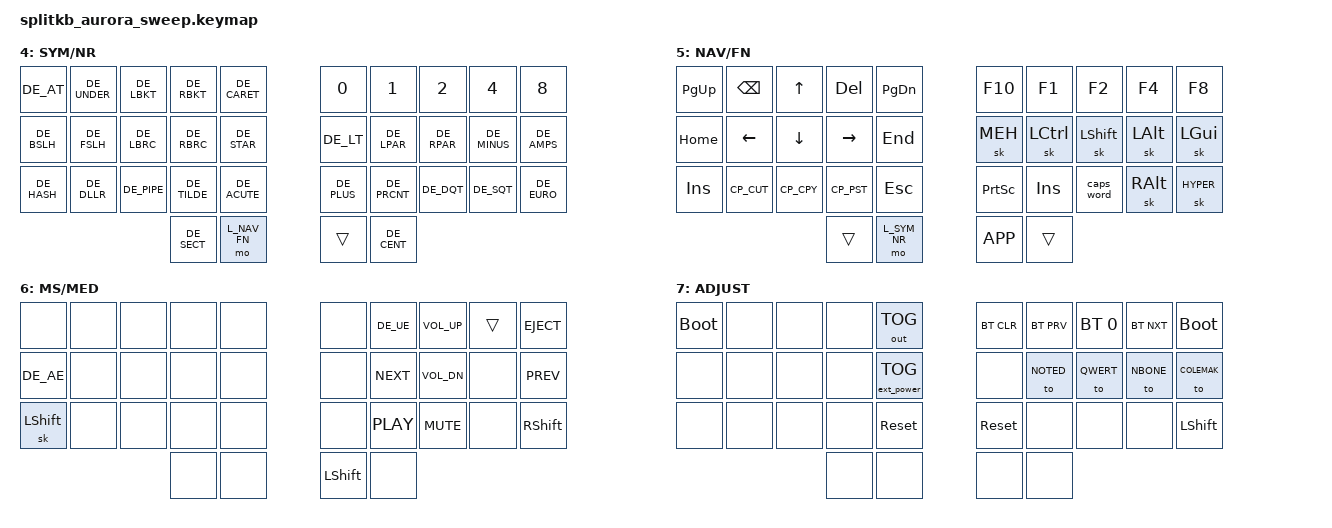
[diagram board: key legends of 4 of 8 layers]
/*
 * Copyright (c) 2022 The ZMK Contributors
 *
 * SPDX-License-Identifier: MIT
 */

#include <behaviors.dtsi>
#include <dt-bindings/zmk/keys.h>
#include <dt-bindings/zmk/bt.h>
#include <dt-bindings/zmk/outputs.h>
/* #include <dt-bindings/zmk/rgb.h> */
#include <dt-bindings/zmk/ext_power.h>
#include "custom_keys.h"
#include "custom_combos.h"

&mt {
  flavor = "tap-preferred";
};
&caps_word {
  continue-list = <DE_UNDER DE_MINUS BACKSPACE DELETE>;
};

// pin 1 is blocked by rgb, so use pin 16 as I have no encoders installed
/* nice_view_spi: &spi0 {
                  compatible = "nordic,nrf-spim";
                  pinctrl-0 = <&spi0_default>;
                  pinctrl-1 = <&spi0_sleep>;
                  pinctrl-names = "default", "sleep";
                  cs-gpios = <&pro_micro 16 GPIO_ACTIVE_HIGH>;  // default is D1 in the pinout
              }; */

/ {
  conditional_layers {
    compatible = "zmk,conditional-layers";
    tri_layer {
      if-layers = <L_SYM_NR L_NAV_FN>;
      then-layer = <L_ADJUST>;
    };
  };

  keymap {
    compatible = "zmk,keymap";

    // 0. NOTED
    noted_layer {
      display-name = "NOTED";
      bindings = <
        // ┌─────┬─────┬─────┬─────┬─────┐     ┌─────┬─────┬─────┬─────┬─────┐
        // │  x  │  v  │  l  │  c  │  w  │     │  k  │  h  │  g  │ 4/f │  q  │
        // ├─────┼─────┼─────┼─────┼─────┤     ├─────┼─────┼─────┼─────┼─────┤
        // │  u  │  i  │  a  │  e  │  o  │     │  s  │  n  │  r  │  t  │  d  │
        // ├─────┼─────┼─────┼─────┼─────┤     ├─────┼─────┼─────┼─────┼─────┤
        // │  y  │  ö  │  ß  │  p  │  z  │     │  b  │  m  │  ,  │  .  │  j  │
        // └─────┴─────┴─────┼─────┼─────┤     ├─────┼─────┼─────┴─────┴─────┘
        //                   │2/Tab│1/Ret│     │1/Spc│2/Esc│
        //                   └─────┴─────┘     └─────┴─────┘
        &kp DE_X      &kp DE_V      &kp DE_L      &kp DE_C      &kp DE_W          &kp DE_K       &kp DE_H      &kp DE_G        MSMD(DE_F)    &kp DE_Q
        &kp DE_U      &kp DE_I     HRML(DE_A,         DE_E,         DE_O)         HRMR(DE_S,         DE_N,         DE_R)       &kp DE_T      &kp DE_D
        LSH(DE_Y)     &kp DE_OE     &kp DE_SZ     &kp DE_Q      &kp DE_OE         &kp DE_Y       &kp DE_Z      &kp DE_COMMA    &kp DE_DOT    RSH(DE_K)
        /**/                                      NAVFN_TAB     SYMNR_RET         SYMNR_SPC      NAVFN_ESC
        >;
    };

    // 1. QWERTZ
    default_layer {
      display-name = "QWERTZ";
      bindings = <
        // ┌─────┬─────┬─────┬─────┬─────┐     ┌─────┬─────┬─────┬─────┬─────┐
        // │  q  │  w  │  e  │  r  │  t  │     │  z  │  u  │  i  │ 4/o │  p  │
        // ├─────┼─────┼─────┼─────┼─────┤     ├─────┼─────┼─────┼─────┼─────┤
        // │  a  │  s  │  d  │  f  │  g  │     │  h  │  j  │  k  │  l  │  ö  │
        // ├─────┼─────┼─────┼─────┼─────┤     ├─────┼─────┼─────┼─────┼─────┤
        // │  y  │  x  │  c  │  v  │  b  │     │  n  │  m  │  ,  │  .  │  ß  │
        // └─────┴─────┴─────┼─────┼─────┤     ├─────┼─────┼─────┴─────┴─────┘
        //                   │2/Tab│1/Ret│     │1/Spc│2/Esc│
        //                   └─────┴─────┘     └─────┴─────┘
        &kp DE_Q      &kp DE_W      &kp DE_E      &kp DE_R      &kp DE_T          &kp DE_Z       &kp DE_U      &kp DE_I        MSMD(DE_O)    &kp DE_P
        &kp DE_A      &kp DE_S     HRML(DE_D,         DE_F,         DE_G)         HRMR(DE_H,         DE_J,         DE_K)       &kp DE_L      &kp DE_OE
        LSH(DE_Y)     &kp DE_X      &kp DE_C      &kp DE_V      &kp DE_B          &kp DE_N       &kp DE_M      &kp DE_COMMA    &kp DE_DOT    RSH(DE_SZ)
        /**/                                      NAVFN_TAB     SYMNR_RET         SYMNR_SPC      NAVFN_ESC
        >;
    };

    // 2. BONE
    bone_layer {
      display-name = "BONE";
      bindings = <
        // ┌─────┬─────┬─────┬─────┬─────┐     ┌─────┬─────┬─────┬─────┬─────┐
        // │  j  │  d  │  u  │  a  │  x  │     │  p  │  h  │  l  │ 4/m │  w  │
        // ├─────┼─────┼─────┼─────┼─────┤     ├─────┼─────┼─────┼─────┼─────┤
        // │  c  │  t  │  i  │  e  │  o  │     │  b  │  n  │  r  │  s  │  g  │
        // ├─────┼─────┼─────┼─────┼─────┤     ├─────┼─────┼─────┼─────┼─────┤
        // │  f  │  v  │  ß  │  q  │  ö  │     │  y  │  z  │  ,  │  .  │  k  │
        // └─────┴─────┴─────┼─────┼─────┤     ├─────┼─────┼─────┴─────┴─────┘
        //                   │2/Tab│1/Ret│     │1/Spc│2/Esc│
        //                   └─────┴─────┘     └─────┴─────┘
        &kp DE_J      &kp DE_D      &kp DE_U      &kp DE_A      &kp DE_X          &kp DE_P       &kp DE_H      &kp DE_L        MSMD(DE_M)    &kp DE_W
        &kp DE_C      &kp DE_T     HRML(DE_I,         DE_E,         DE_O)         HRMR(DE_B,         DE_N,         DE_R)       &kp DE_S      &kp DE_G
        LSH(DE_F)     &kp DE_V      &kp DE_SZ     &kp DE_Q      &kp DE_OE         &kp DE_Y       &kp DE_Z      &kp DE_COMMA    &kp DE_DOT    RSH(DE_K)
        /**/                                      NAVFN_TAB     SYMNR_RET         SYMNR_SPC      NAVFN_ESC
        >;
    };

    // 3. COLEMAK
    colemak_layer {
      display-name = "COLEMAK";
      bindings = <
        // ┌─────┬─────┬─────┬─────┬─────┐     ┌─────┬─────┬─────┬─────┬─────┐
        // │  q  │  w  │  f  │  p  │  b  │     │  j  │  l  │  u  │ 4/z │  ö  │
        // ├─────┼─────┼─────┼─────┼─────┤     ├─────┼─────┼─────┼─────┼─────┤
        // │  a  │  r  │  s  │  t  │  g  │     │  m  │  n  │  e  │  i  │  o  │
        // ├─────┼─────┼─────┼─────┼─────┤     ├─────┼─────┼─────┼─────┼─────┤
        // │  y  │  x  │  c  │  v  │  b  │     │  n  │  m  │  ,  │  .  │  ß  │
        // └─────┴─────┴─────┼─────┼─────┤     ├─────┼─────┼─────┴─────┴─────┘
        //                   │2/Tab│1/Ret│     │1/Spc│2/Esc│
        //                   └─────┴─────┘     └─────┴─────┘
        &kp DE_Q      &kp DE_W      &kp DE_F      &kp DE_P      &kp DE_B          &kp DE_J       &kp DE_L      &kp DE_U        MSMD(DE_Z)    &kp DE_OE
        &kp DE_A      &kp DE_R     HRML(DE_S,         DE_T,         DE_G)         HRMR(DE_M,         DE_N,         DE_E)       &kp DE_I      &kp DE_O
        LSH(DE_Y)     &kp DE_X      &kp DE_C      &kp DE_D      &kp DE_V          &kp DE_K       &kp DE_H      &kp DE_COMMA    &kp DE_DOT    RSH(DE_SZ)
        /**/                                      NAVFN_TAB     SYMNR_RET         SYMNR_SPC      NAVFN_ESC
        >;
    };

    // 4. L_SYM_NR
    symbol_number_layer {
      display-name = "SYM/NR";
      bindings = <
        // ┌─────┬─────┬─────┬─────┬─────┐     ┌─────┬─────┬─────┬─────┬─────┐
        // │  @  │  _  │  [  │  ]  │ ^ ° │     │ 0 = │ 1 ! │ 2 " │ 4 $ │ 8 ( │
        // ├─────┼─────┼─────┼─────┼─────┤     ├─────┼─────┼─────┼─────┼─────┤
        // │  \  │  /  │  {  │  }  │  *  │     │ < > │  (  │  )  │ - _ │  &  │
        // ├─────┼─────┼─────┼─────┼─────┤     ├─────┼─────┼─────┼─────┼─────┤
        // │ # ' │  $  │  |  │  ~  │  ´  │     │ + * │  %  │  "  │  '  │  €  │
        // └─────┴─────┴─────┼─────┼─────┤     ├─────┼─────┼─────┴─────┴─────┘
        //                   │ (§) │ ___ │     │ ___ │  ¢  │
        //                   └─────┴─────┘     └─────┴─────┘
        &kp DE_AT     &kp DE_UNDER  &kp DE_LBKT   &kp DE_RBKT   &kp DE_CARET      &kp N0        &kp N1        &kp N2        &kp N4        &kp N8
        &kp DE_BSLH   &kp DE_FSLH   &kp DE_LBRC   &kp DE_RBRC   &kp DE_STAR       &kp DE_LT     &kp DE_LPAR   &kp DE_RPAR   &kp DE_MINUS  &kp DE_AMPS
        &kp DE_HASH   &kp DE_DLLR   &kp DE_PIPE   &kp DE_TILDE  &kp DE_ACUTE      &kp DE_PLUS   &kp DE_PRCNT  &kp DE_DQT    &kp DE_SQT    &kp DE_EURO
                                                  &kp DE_SECT   &mo L_NAV_FN      &trans        &kp DE_CENT
        >;
    };

    // 5. L_NAV_FN
    navigation_function_layer {
      display-name = "NAV/FN";
      bindings = <
        // ┌─────┬─────┬─────┬─────┬─────┐     ┌─────┬─────┬─────┬─────┬─────┐
        // │PgUp │ BSp │  ↑  │ Del │PgDn │     │ F10 │  F1 │  F2 │  F4 │  F8 │
        // ├─────┼─────┼─────┼─────┼─────┤     ├─────┼─────┼─────┼─────┼─────┤
        // │Home │  ←  │  ↓  │  →  │ End │     │OsMeh│OsCtl│OsSft│OsAlt│OsGui│
        // ├─────┼─────┼─────┼─────┼─────┤     ├─────┼─────┼─────┼─────┼─────┤
        // │ Ins │ Cut │Copy │Paste│ ESC │     │PrScr│ Ins │CapsW│OsAGr│OsHyp│
        // └─────┴─────┴─────┼─────┼─────┤     ├─────┼─────┼─────┴─────┴─────┘
        //                   │     │     │     │ App │     │
        //                   └─────┴─────┘     └─────┴─────┘
        &kp PG_UP   &kp BSPC    &kp UP      &kp DEL     &kp PG_DN     &kp F10    &kp F1     &kp F2       &kp F4     &kp F8
        &kp HOME    &kp LEFT    &kp DOWN    &kp RIGHT   &kp END       &sk MEH    &sk LCTRL  &sk LSHFT    &sk LALT   &sk LGUI
        &kp INS     &kp CP_CUT  &kp CP_CPY  &kp CP_PST  &kp ESC       &kp PSCRN  &kp INS    &caps_word   &sk RALT   &sk HYPER
                                                  &trans        &mo L_SYM_NR      &kp K_APP    &trans
        >;
    };

    // 6. L_MS_MED
    mouse_media_layer {
      display-name = "MS/MED";
      bindings = <
        // ┌─────┬─────┬─────┬─────┬─────┐     ┌─────┬─────┬─────┬─────┬─────┐
        // │ vvv │ <<< │  ↑  │ >>> │ ^^^ │     │MsSp+│  ü  │ Vol+│ (v) │Eject│
        // ├─────┼─────┼─────┼─────┼─────┤     ├─────┼─────┼─────┼─────┼─────┤
        // │  ä  │  ←  │  ↓  │  →  │Pause│     │MsSpN│ Next│ Vol-│ XXX │ Prev│
        // ├─────┼─────┼Mouse┼─────┼─────┤     ├─────┼─────┼─────┼─────┼─────┤
        // │LShft│ MB4 │ MB3 │ MB5 │SrlLk│     │MsSp-│ Play│ Mute│ XXX │RShft│
        // └─────┴─────┴─────┼─────┼─────┤     ├─────┼─────┼─────┴─────┴─────┘
        //                   │ MB2 │ MB1 │     │LShft│ MB3 │
        //                   └─────┴─────┘     └─────┴─────┘
        &none         &none         &none         &none         &none             &none         &kp DE_UE     &kp C_VOL_UP  &trans   &kp C_EJECT
        &kp DE_AE     &none         &none         &none         &none             &none         &kp C_NEXT    &kp C_VOL_DN  &none    &kp C_PREV
        &sk LSHIFT    &none         &none         &none         &none             &none         &kp C_PLAY    &kp C_MUTE    &none    &kp RSHFT
                                                  &none         &none             &kp LSHFT     &none
        >;
    };

    // 7. L_ADJUST
    keyboard_config_layer {
      display-name = "ADJUST";
      bindings = <
        // ┌─────┬─────┬─────┬─────┬─────┐     ┌─────┬─────┬─────┬─────┬─────┐
        // │BOOTL│(Md-)│(Md+)│ XXX │ B/U │     │ BtC │ Bt← │ Bt0 │ Bt→ │BOOTL│
        // ├─────┼─────┼─────┼─────┼─────┤     ├─────┼─────┼─────┼─────┼─────┤
        // │(Sp+)│(Vl+)│(St+)│(Hu+)│ TOGG│     │ XXX │NOTED│QWERT│NBONE│COLMK│
        // ├─────┼─────┼─────┼─────┼─────┤     ├─────┼─────┼─────┼─────┼─────┤
        // │(Sp-)│(Vl-)│(St-)│(Hu-)│RESET│     │RESET│ XXX │ XXX │ XXX │ Sft │
        // └─────┴─────┴─────┼─────┼─────┤     ├─────┼─────┼─────┴─────┴─────┘
        //                   │     │     │     │     │     │
        //                   └─────┴─────┘     └─────┴─────┘
        &bootloader   &none    &none  &none         &out OUT_TOG         &bt BT_CLR    &bt BT_PRV    &bt BT_SEL 0  &bt BT_NXT    &bootloader
        &none         &none    &none  &none         &ext_power EP_TOG    &none         &to NOTED     &to QWERT     &to NBONE     &to COLEMAK
        &none         &none    &none  &none         &sys_reset           &sys_reset    &none         &none         &none         &kp LSHFT

        // &bootloader      &none            &none            &sys_reset       &rgb_ug RGB_TOG      &bootloader   &bt BT_SEL 1  &bt BT_SEL 2  &bt BT_SEL 3  &bt BT_SEL 4
        // &rgb_ug RGB_SPI  &rgb_ug RGB_BRI  &rgb_ug RGB_SAI  &rgb_ug RGB_HUI  &rgb_ug RGB_EFF      &bt BT_CLR    &bt BT_PRV    &bt BT_SEL 0  &bt BT_NXT    &out OUT_TOG
        // &rgb_ug RGB_SPD  &rgb_ug RGB_BRD  &rgb_ug RGB_SAD  &rgb_ug RGB_HUD  &rgb_ug RGB_EFR      &sys_reset    &none         &none         &none         &kp LSHFT
                                                  &none         &none             &none         &none
        >;
    };

  };

};
